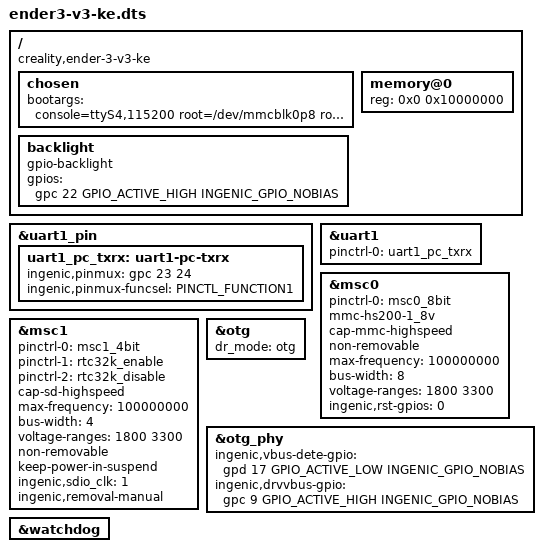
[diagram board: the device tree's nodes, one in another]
/dts-v1/;

#include <dt-bindings/gpio/gpio.h>
#include "x2000.dtsi"

/ {
	compatible = "creality,ender-3-v3-ke", "ingenic,x2000";

	chosen {
		/* UART1 is reserved for the printer MCU and must not be the console. */
		bootargs = "console=ttyS4,115200 root=/dev/mmcblk0p8 rootwait rootfstype=squashfs ro";
	};

	backlight {
		compatible = "gpio-backlight";
		gpios = <&gpc 22 GPIO_ACTIVE_HIGH INGENIC_GPIO_NOBIAS>;
	};

	memory@0 {
		device_type = "memory";
		reg = <0x0 0x10000000>;
	};
};

&uart1_pin {
	uart1_pc_txrx: uart1-pc-txrx {
		ingenic,pinmux = <&gpc 23 24>;
		ingenic,pinmux-funcsel = <PINCTL_FUNCTION1>;
	};
};

&uart1 {
	status = "okay";
	pinctrl-names = "default";
	pinctrl-0 = <&uart1_pc_txrx>;
};

&msc0 {
	status = "okay";
	pinctrl-names = "default";
	pinctrl-0 = <&msc0_8bit>;
	mmc-hs200-1_8v;
	cap-mmc-highspeed;
	non-removable;
	max-frequency = <100000000>;
	bus-width = <8>;
	voltage-ranges = <1800 3300>;
	ingenic,rst-gpios = <0>;
};

&msc1 {
	status = "okay";
	pinctrl-names = "default", "enable", "disable";
	pinctrl-0 = <&msc1_4bit>;
	pinctrl-1 = <&rtc32k_enable>;
	pinctrl-2 = <&rtc32k_disable>;
	cap-sd-highspeed;
	max-frequency = <100000000>;
	bus-width = <4>;
	voltage-ranges = <1800 3300>;
	non-removable;
	keep-power-in-suspend;
	ingenic,sdio_clk = <1>;
	ingenic,removal-manual;
};

&otg {
	dr_mode = "otg";
	status = "okay";
};

&otg_phy {
	/*
	 * Ender-3 V3 KE USB PHY wiring. GPC9 is not guessed: NebulaOS/OpenKE
	 * documents it as the VBUS-drive GPIO derived from the real Stock DTB:
	 * coreflake1/NebulaOS-kernel, commit
	 * c902097d1a79c21ef6717d7e4ecc1db2a9233990:
	 * https://github.com/coreflake1/NebulaOS-kernel/commit/c902097d1a79c21ef6717d7e4ecc1db2a9233990
	 *
	 * Fre3nder independently checked that the pinned X2000 USB PHY driver
	 * consumes this property with matching active-high semantics. GPD17
	 * VBUS-detect is likewise taken from that documented board configuration
	 * and checked against the local driver semantics.
	 */
	status = "okay";
	ingenic,vbus-dete-gpio = <&gpd 17 GPIO_ACTIVE_LOW INGENIC_GPIO_NOBIAS>;
	ingenic,drvvbus-gpio = <&gpc 9 GPIO_ACTIVE_HIGH INGENIC_GPIO_NOBIAS>;
};

&watchdog {
	status = "okay";
};
